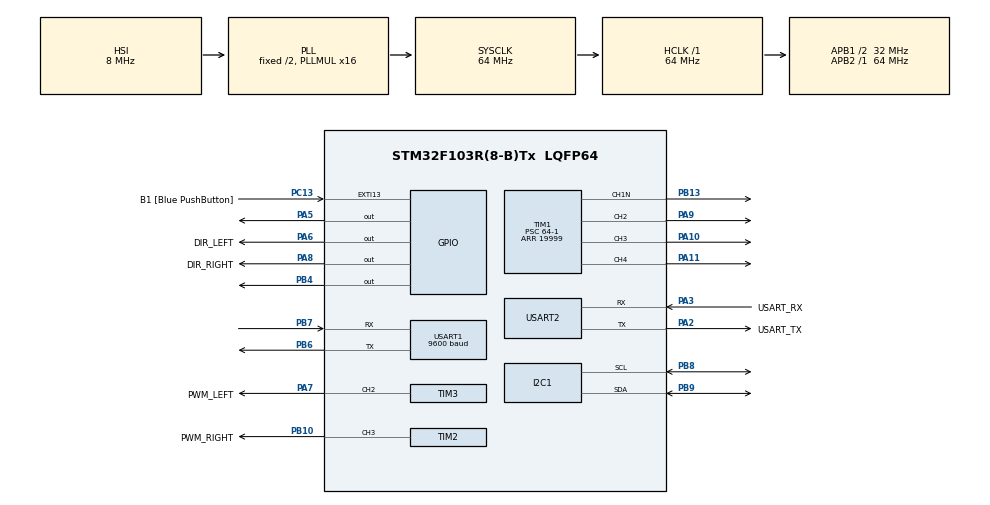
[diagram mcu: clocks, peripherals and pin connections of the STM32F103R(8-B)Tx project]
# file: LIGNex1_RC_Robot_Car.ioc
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Dma.Request0=USART1_RX
Dma.USART1_RX.0.Direction=DMA_PERIPH_TO_MEMORY
Dma.USART1_RX.0.Instance=DMA1_Channel5
Dma.USART1_RX.0.MemDataAlignment=DMA_MDATAALIGN_BYTE
Dma.USART1_RX.0.MemInc=DMA_MINC_ENABLE
Dma.USART1_RX.0.Mode=DMA_NORMAL
Dma.USART1_RX.0.PeriphDataAlignment=DMA_PDATAALIGN_BYTE
Dma.USART1_RX.0.PeriphInc=DMA_PINC_DISABLE
Dma.USART1_RX.0.Priority=DMA_PRIORITY_LOW
FREERTOS.Queues01=RxQhandle,16,uint8_t,0,Dynamic,NULL,NULL;ServoQ,16,Servo_type,0,Dynamic,NULL,NULL;MoterQ,16,Moter_type,0,Dynamic,NULL,NULL
FREERTOS.Tasks01=DriveTask,24,128,DriveTaskHandler,As weak,NULL,Static,DriveTaskBuffer,DriveTaskControlBlock;BluetoothRxTask,8,128,BluetoothRxTaskHandler,As external,NULL,Static,BluetoothRxTaskBuffer,BluetoothRxTaskControlBlock;RobotArmTask,8,128,RobotArmTaskHandler,As external,NULL,Static,RobotArmTaskBuffer,RobotArmTaskControlBlock
FREERTOS.configMAX_TASK_NAME_LEN=32
Mcu.Family=STM32F1
Mcu.Name=STM32F103R(8-B)Tx
Mcu.Package=LQFP64
NVIC.DMA1_Channel5_IRQn=true\:5\:0\:false\:false\:true\:true\:false\:true\:true
NVIC.EXTI15_10_IRQn=true\:5\:0\:false\:false\:true\:true\:true\:true\:true
NVIC.PriorityGroup=NVIC_PRIORITYGROUP_4
NVIC.TIM4_IRQn=true\:15\:0\:false\:false\:true\:false\:false\:true\:true
NVIC.TimeBase=TIM4_IRQn
NVIC.TimeBaseIP=TIM4
NVIC.USART1_IRQn=true\:5\:0\:false\:false\:true\:true\:true\:true\:true
NVIC.USART2_IRQn=true\:5\:0\:false\:false\:true\:true\:true\:true\:true
PA10.Signal=S_TIM1_CH3
PA11.Signal=S_TIM1_CH4
PA13.GPIO_Label=TMS
PA13.Mode=Serial_Wire
PA13.Signal=SYS_JTMS-SWDIO
PA14.GPIO_Label=TCK
PA14.Mode=Serial_Wire
PA14.Signal=SYS_JTCK-SWCLK
PA2.GPIO_Label=USART_TX
PA2.GPIO_Mode=GPIO_MODE_AF_PP
PA2.GPIO_PuPd=GPIO_NOPULL
PA2.GPIO_Speed=GPIO_SPEED_FREQ_LOW
PA2.Mode=Asynchronous
PA2.Signal=USART2_TX
PA3.GPIO_Label=USART_RX
PA3.GPIO_Mode=GPIO_MODE_AF_PP
PA3.GPIO_PuPd=GPIO_NOPULL
PA3.GPIO_Speed=GPIO_SPEED_FREQ_LOW
PA3.Mode=Asynchronous
PA3.Signal=USART2_RX
PA5.Signal=GPIO_Output
PA6.GPIO_Label=DIR_LEFT
PA6.Signal=GPIO_Output
PA7.GPIO_Label=PWM_LEFT
PA7.Signal=S_TIM3_CH2
PA8.GPIO_Label=DIR_RIGHT
PA8.Signal=GPIO_Output
PA9.Signal=S_TIM1_CH2
PB10.GPIO_Label=PWM_RIGHT
PB10.Signal=S_TIM2_CH3
PB13.Mode=PWM Generation1 CH1N
PB13.Signal=TIM1_CH1N
PB3.GPIO_Label=SWO
PB3.Signal=SYS_JTDO-TRACESWO
PB4.Signal=GPIO_Output
PB6.Mode=Asynchronous
PB6.Signal=USART1_TX
PB7.Mode=Asynchronous
PB7.Signal=USART1_RX
PB8.Mode=I2C
PB8.Signal=I2C1_SCL
PB9.Mode=I2C
PB9.Signal=I2C1_SDA
PC13-TAMPER-RTC.GPIO_Label=B1 [Blue PushButton]
PC13-TAMPER-RTC.GPIO_PuPd=GPIO_NOPULL
PC13-TAMPER-RTC.Signal=GPXTI13
PC14-OSC32_IN.Mode=LSE-External-Oscillator
PC14-OSC32_IN.Signal=RCC_OSC32_IN
PC15-OSC32_OUT.Mode=LSE-External-Oscillator
PC15-OSC32_OUT.Signal=RCC_OSC32_OUT
PD0-OSC_IN.Mode=HSE-External-Clock-Source
PD0-OSC_IN.Signal=RCC_OSC_IN
PD1-OSC_OUT.Mode=HSE-External-Clock-Source
PD1-OSC_OUT.Signal=RCC_OSC_OUT
ProjectManager.HeapSize=0x200
ProjectManager.StackSize=0x400
ProjectManager.TargetToolchain=CMake
RCC.AHBFreq_Value=64000000
RCC.APB1CLKDivider=RCC_HCLK_DIV2
RCC.APB1Freq_Value=32000000
RCC.APB1TimFreq_Value=64000000
RCC.APB2Freq_Value=64000000
RCC.APB2TimFreq_Value=64000000
RCC.HCLKFreq_Value=64000000
RCC.PLLMUL=RCC_PLL_MUL16
RCC.RTCClockSelection=RCC_RTCCLKSOURCE_LSE
RCC.SYSCLKFreq_VALUE=64000000
RCC.SYSCLKSource=RCC_SYSCLKSOURCE_PLLCLK
RCC.USBFreq_Value=64000000
SH.S_TIM1_CH2.0=TIM1_CH2,PWM Generation2 CH2
SH.S_TIM1_CH3.0=TIM1_CH3,PWM Generation3 CH3
SH.S_TIM1_CH4.0=TIM1_CH4,PWM Generation4 CH4
SH.S_TIM2_CH3.0=TIM2_CH3,PWM Generation3 CH3
SH.S_TIM3_CH2.0=TIM3_CH2,PWM Generation2 CH2
TIM1.AutoReloadPreload=TIM_AUTORELOAD_PRELOAD_ENABLE
TIM1.Channel-PWM\ Generation1\ CH1N=TIM_CHANNEL_1
TIM1.Channel-PWM\ Generation2\ CH2=TIM_CHANNEL_2
TIM1.Channel-PWM\ Generation3\ CH3=TIM_CHANNEL_3
TIM1.Channel-PWM\ Generation4\ CH4=TIM_CHANNEL_4
TIM1.Period=19999
TIM1.Prescaler=64-1
TIM2.Channel-PWM\ Generation3\ CH3=TIM_CHANNEL_3
TIM2.Period=999
TIM2.Prescaler=2
TIM3.Channel-PWM\ Generation2\ CH2=TIM_CHANNEL_2
TIM3.Period=999
TIM3.Prescaler=2
USART1.BaudRate=9600
USART1.VirtualMode=VM_ASYNC
USART2.VirtualMode=VM_ASYNC
VP_FREERTOS_VS_CMSIS_V2.Mode=CMSIS_V2
VP_SYS_VS_tim4.Mode=TIM4
VP_TIM1_VS_ClockSourceINT.Mode=Internal
VP_TIM2_VS_ClockSourceINT.Mode=Internal
VP_TIM3_VS_ClockSourceINT.Mode=Internal
board=NUCLEO-F103RB

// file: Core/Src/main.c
/* USER CODE BEGIN Header */
/**
  ******************************************************************************
  * @file           : main.c
  * @brief          : Main program body
  ******************************************************************************
  * @attention
  *
  * Copyright (c) 2026 STMicroelectronics.
  * All rights reserved.
  *
  * This software is licensed under terms that can be found in the LICENSE file
  * in the root directory of this software component.
  * If no LICENSE file comes with this software, it is provided AS-IS.
  *
  ******************************************************************************
  */
/* USER CODE END Header */
#include "main.h"
#include "cmsis_os.h"
#include "dma.h"
#include "i2c.h"
#include "tim.h"
#include "usart.h"
#include "gpio.h"

void SystemClock_Config(void);
void MX_FREERTOS_Init(void);

int main(void)
{

  /* MCU Configuration--------------------------------------------------------*/

  /* Reset of all peripherals, Initializes the Flash interface and the Systick. */
  HAL_Init();

  /* Configure the system clock */
  SystemClock_Config();

  /* Initialize all configured peripherals */
  MX_GPIO_Init();
  MX_DMA_Init();
  MX_USART2_UART_Init();
  MX_USART1_UART_Init();
  MX_I2C1_Init();
  MX_TIM2_Init();
  MX_TIM3_Init();
  MX_TIM1_Init();

  /* Init scheduler */
  osKernelInitialize();  /* Call init function for freertos objects (in cmsis_os2.c) */
  MX_FREERTOS_Init();

  /* Start scheduler */
  osKernelStart();

  /* We should never get here as control is now taken by the scheduler */

  /* Infinite loop */
  while (1)
  {

  }
}

void SystemClock_Config(void)
{
  RCC_OscInitTypeDef RCC_OscInitStruct = {0};
  RCC_ClkInitTypeDef RCC_ClkInitStruct = {0};

  /** Initializes the RCC Oscillators according to the specified parameters
  * in the RCC_OscInitTypeDef structure.
  */
  RCC_OscInitStruct.OscillatorType = RCC_OSCILLATORTYPE_HSI;
  RCC_OscInitStruct.HSIState = RCC_HSI_ON;
  RCC_OscInitStruct.HSICalibrationValue = RCC_HSICALIBRATION_DEFAULT;
  RCC_OscInitStruct.PLL.PLLState = RCC_PLL_ON;
  RCC_OscInitStruct.PLL.PLLSource = RCC_PLLSOURCE_HSI_DIV2;
  RCC_OscInitStruct.PLL.PLLMUL = RCC_PLL_MUL16;
  if (HAL_RCC_OscConfig(&RCC_OscInitStruct) != HAL_OK)
  {
    Error_Handler();
  }

  /** Initializes the CPU, AHB and APB buses clocks
  */
  RCC_ClkInitStruct.ClockType = RCC_CLOCKTYPE_HCLK|RCC_CLOCKTYPE_SYSCLK
                              |RCC_CLOCKTYPE_PCLK1|RCC_CLOCKTYPE_PCLK2;
  RCC_ClkInitStruct.SYSCLKSource = RCC_SYSCLKSOURCE_PLLCLK;
  RCC_ClkInitStruct.AHBCLKDivider = RCC_SYSCLK_DIV1;
  RCC_ClkInitStruct.APB1CLKDivider = RCC_HCLK_DIV2;
  RCC_ClkInitStruct.APB2CLKDivider = RCC_HCLK_DIV1;

  if (HAL_RCC_ClockConfig(&RCC_ClkInitStruct, FLASH_LATENCY_2) != HAL_OK)
  {
    Error_Handler();
  }
}

void HAL_TIM_PeriodElapsedCallback(TIM_HandleTypeDef *htim)
{
  if (htim->Instance == TIM4)
  {
    HAL_IncTick();
  }
}

void Error_Handler(void)
{
  __disable_irq();
  while (1)
  {
  }
}

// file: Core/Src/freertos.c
/* USER CODE BEGIN Header */
/**
  ******************************************************************************
  * File Name          : freertos.c
  * Description        : Code for freertos applications
  ******************************************************************************
  * @attention
  *
  * Copyright (c) 2026 STMicroelectronics.
  * All rights reserved.
  *
  * This software is licensed under terms that can be found in the LICENSE file
  * in the root directory of this software component.
  * If no LICENSE file comes with this software, it is provided AS-IS.
  *
  ******************************************************************************
  */
/* USER CODE END Header */

#include "FreeRTOS.h"
#include "task.h"
#include "main.h"
#include "cmsis_os.h"

/* USER CODE BEGIN Includes */
#include "DataConfig.hpp"

/* USER CODE END Includes */

typedef StaticTask_t osStaticThreadDef_t;

/* Definitions for DriveTask */
osThreadId_t DriveTaskHandle;
uint32_t DriveTaskBuffer[ 128 ];
osStaticThreadDef_t DriveTaskControlBlock;
const osThreadAttr_t DriveTask_attributes = {
  .name = "DriveTask",
  .cb_mem = &DriveTaskControlBlock,
  .cb_size = sizeof(DriveTaskControlBlock),
  .stack_mem = &DriveTaskBuffer[0],
  .stack_size = sizeof(DriveTaskBuffer),
  .priority = (osPriority_t) osPriorityNormal,
};
/* Definitions for BluetoothRxTask */
osThreadId_t BluetoothRxTaskHandle;
uint32_t BluetoothRxTaskBuffer[ 128 ];
osStaticThreadDef_t BluetoothRxTaskControlBlock;
const osThreadAttr_t BluetoothRxTask_attributes = {
  .name = "BluetoothRxTask",
  .cb_mem = &BluetoothRxTaskControlBlock,
  .cb_size = sizeof(BluetoothRxTaskControlBlock),
  .stack_mem = &BluetoothRxTaskBuffer[0],
  .stack_size = sizeof(BluetoothRxTaskBuffer),
  .priority = (osPriority_t) osPriorityLow,
};
/* Definitions for RobotArmTask */
osThreadId_t RobotArmTaskHandle;
uint32_t RobotArmTaskBuffer[ 128 ];
osStaticThreadDef_t RobotArmTaskControlBlock;
const osThreadAttr_t RobotArmTask_attributes = {
  .name = "RobotArmTask",
  .cb_mem = &RobotArmTaskControlBlock,
  .cb_size = sizeof(RobotArmTaskControlBlock),
  .stack_mem = &RobotArmTaskBuffer[0],
  .stack_size = sizeof(RobotArmTaskBuffer),
  .priority = (osPriority_t) osPriorityLow,
};
/* Definitions for RxQhandle */
osMessageQueueId_t RxQhandleHandle;
const osMessageQueueAttr_t RxQhandle_attributes = {
  .name = "RxQhandle"
};
/* Definitions for ServoQ */
osMessageQueueId_t ServoQHandle;
const osMessageQueueAttr_t ServoQ_attributes = {
  .name = "ServoQ"
};
/* Definitions for MoterQ */
osMessageQueueId_t MoterQHandle;
const osMessageQueueAttr_t MoterQ_attributes = {
  .name = "MoterQ"
};

void DriveTaskHandler(void *argument);
extern void BluetoothRxTaskHandler(void *argument);
extern void RobotArmTaskHandler(void *argument);

void MX_FREERTOS_Init(void); /* (MISRA C 2004 rule 8.1) */

void MX_FREERTOS_Init(void) {

  /* Create the queue(s) */
  /* creation of RxQhandle */
  RxQhandleHandle = osMessageQueueNew (16, sizeof(uint8_t), &RxQhandle_attributes);

  /* creation of ServoQ */
  ServoQHandle = osMessageQueueNew (16, sizeof(Servo_type), &ServoQ_attributes);

  /* creation of MoterQ */
  MoterQHandle = osMessageQueueNew (16, sizeof(Moter_type), &MoterQ_attributes);

  /* Create the thread(s) */
  /* creation of DriveTask */
  DriveTaskHandle = osThreadNew(DriveTaskHandler, NULL, &DriveTask_attributes);

  /* creation of BluetoothRxTask */
  BluetoothRxTaskHandle = osThreadNew(BluetoothRxTaskHandler, NULL, &BluetoothRxTask_attributes);

  /* creation of RobotArmTask */
  RobotArmTaskHandle = osThreadNew(RobotArmTaskHandler, NULL, &RobotArmTask_attributes);

}

__weak void DriveTaskHandler(void *argument)
{
  for(;;)
  {
    osDelay(1);
  }
}
